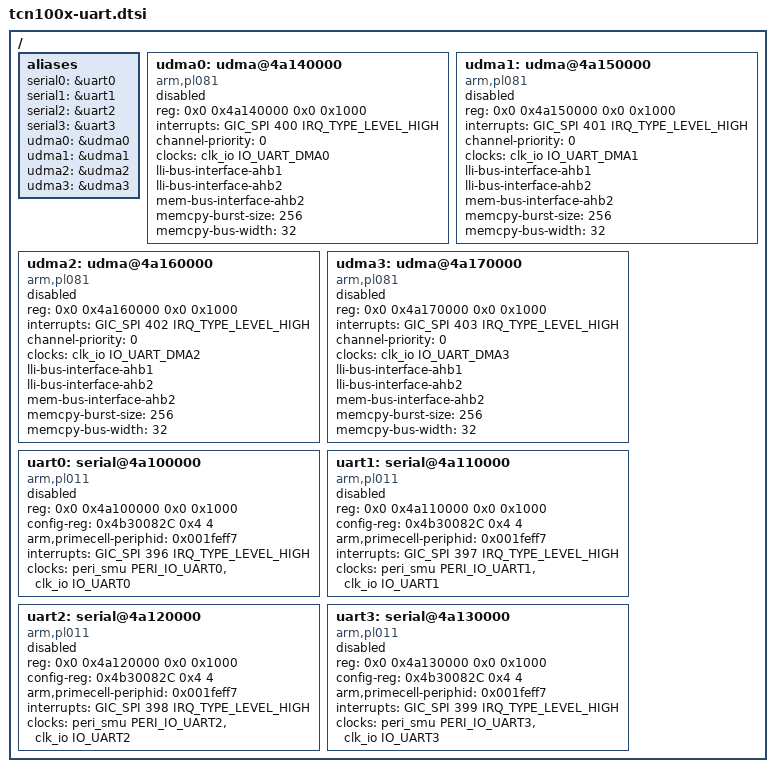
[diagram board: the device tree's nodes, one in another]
// SPDX-License-Identifier: (GPL-2.0-or-later OR MIT)
/*
 * Copyright (C) 2023 Telechips Inc.
 */

#include <dt-bindings/interrupt-controller/arm-gic.h>

/ {
	aliases: aliases {
		serial0 = &uart0;
		serial1 = &uart1;
		serial2 = &uart2;
		serial3 = &uart3;
		udma0 = &udma0;
		udma1 = &udma1;
		udma2 = &udma2;
		udma3 = &udma3;
	};

	udma0: udma@4a140000 {
		compatible = "arm,pl081", "arm,primecell";
		reg = <0x0 0x4a140000 0x0 0x1000>;
		interrupts = <GIC_SPI 400 IRQ_TYPE_LEVEL_HIGH>;
		//dma-channels = <2>;
		//dma-requests = <32>;
		channel-priority = <0>;
		clocks = <&clk_io IO_UART_DMA0>;
		clock-names = "apb_pclk";
		lli-bus-interface-ahb1;
		lli-bus-interface-ahb2;
		mem-bus-interface-ahb2;
		memcpy-burst-size = <256>;
		memcpy-bus-width = <32>;
		#dma-cells = <2>;
		status = "disabled";
	};

	udma1: udma@4a150000 {
		compatible = "arm,pl081", "arm,primecell";
		reg = <0x0 0x4a150000 0x0 0x1000>;
		interrupts = <GIC_SPI 401 IRQ_TYPE_LEVEL_HIGH>;
		//dma-channels = <2>;
		//dma-requests = <32>;
		channel-priority = <0>;
		clocks = <&clk_io IO_UART_DMA1>;
		clock-names = "apb_pclk";
		lli-bus-interface-ahb1;
		lli-bus-interface-ahb2;
		mem-bus-interface-ahb2;
		memcpy-burst-size = <256>;
		memcpy-bus-width = <32>;
		#dma-cells = <2>;
		status = "disabled";
	};

	udma2: udma@4a160000 {
		compatible = "arm,pl081", "arm,primecell";
		reg = <0x0 0x4a160000 0x0 0x1000>;
		interrupts = <GIC_SPI 402 IRQ_TYPE_LEVEL_HIGH>;
		//dma-channels = <2>;
		//dma-requests = <32>;
		channel-priority = <0>;
		clocks = <&clk_io IO_UART_DMA2>;
		clock-names = "apb_pclk";
		lli-bus-interface-ahb1;
		lli-bus-interface-ahb2;
		mem-bus-interface-ahb2;
		memcpy-burst-size = <256>;
		memcpy-bus-width = <32>;
		#dma-cells = <2>;
		status = "disabled";
	};

	udma3: udma@4a170000 {
		compatible = "arm,pl081", "arm,primecell";
		reg = <0x0 0x4a170000 0x0 0x1000>;
		interrupts = <GIC_SPI 403 IRQ_TYPE_LEVEL_HIGH>;
		//dma-channels = <2>;
		//dma-requests = <32>;
		channel-priority = <0>;
		clocks = <&clk_io IO_UART_DMA3>;
		clock-names = "apb_pclk";
		lli-bus-interface-ahb1;
		lli-bus-interface-ahb2;
		mem-bus-interface-ahb2;
		memcpy-burst-size = <256>;
		memcpy-bus-width = <32>;
		#dma-cells = <2>;
		status = "disabled";
	};

	uart0: serial@4a100000 {
		compatible = "arm,pl011", "arm,primecell";
		reg = <0x0 0x4a100000 0x0 0x1000>;
		config-reg = <0x4b30082C 0x4 4>;
		arm,primecell-periphid = <0x001feff7>;
		interrupts = <GIC_SPI 396 IRQ_TYPE_LEVEL_HIGH>;
		clocks = <&peri_smu PERI_IO_UART0>, <&clk_io IO_UART0>;
		clock-names = "uartclk", "apb_pclk";
		status = "disabled";
	};

	uart1: serial@4a110000 {
		compatible = "arm,pl011", "arm,primecell";
		reg = <0x0 0x4a110000 0x0 0x1000>;
		config-reg = <0x4b30082C 0x4 4>;
		arm,primecell-periphid = <0x001feff7>;
		interrupts = <GIC_SPI 397 IRQ_TYPE_LEVEL_HIGH>;
		clocks = <&peri_smu PERI_IO_UART1>, <&clk_io IO_UART1>;
		clock-names = "uartclk", "apb_pclk";
		status = "disabled";
	};

	uart2: serial@4a120000 {
		compatible = "arm,pl011", "arm,primecell";
		reg = <0x0 0x4a120000 0x0 0x1000>;
		config-reg = <0x4b30082C 0x4 4>;
		arm,primecell-periphid = <0x001feff7>;
		interrupts = <GIC_SPI 398 IRQ_TYPE_LEVEL_HIGH>;
		clocks = <&peri_smu PERI_IO_UART2>, <&clk_io IO_UART2>;
		clock-names = "uartclk", "apb_pclk";
		status = "disabled";
	};

	uart3: serial@4a130000 {
		compatible = "arm,pl011", "arm,primecell";
		reg = <0x0 0x4a130000 0x0 0x1000>;
		config-reg = <0x4b30082C 0x4 4>;
		arm,primecell-periphid = <0x001feff7>;
		interrupts = <GIC_SPI 399 IRQ_TYPE_LEVEL_HIGH>;
		clocks = <&peri_smu PERI_IO_UART3>, <&clk_io IO_UART3>;
		clock-names = "uartclk", "apb_pclk";
		status = "disabled";
	};
};
